# STM32C092 register map
File version: 1.2
CPU: CM0+ r0p0, little endian, MPU, no FPU, 4 interrupt priority bits
Registers are 32-bit, read-write, reset 0x0 unless marked. A register's access mark holds for its fields unless they carry their own. Offsets are from the block's base; [hi:lo] are bit positions; {n}, {i} and the like mark numbered series; 'fields as' and 'values as' point back to an identical list.

## RCC — RCC address block description
Base 0x40021000
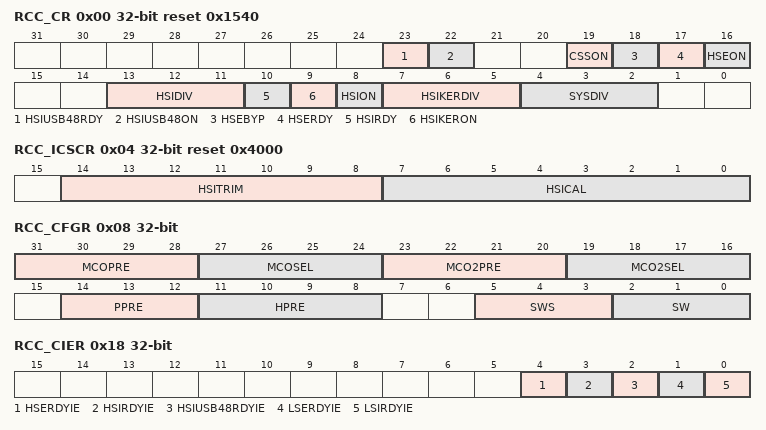
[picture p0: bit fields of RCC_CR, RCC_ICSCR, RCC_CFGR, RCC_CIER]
0x00 RCC_CR reset 0x1540 — RCC clock control register
  [23] HSIUSB48RDY — HSIUSB48 clock ready flag Set by hardware when the HSIUSB48 oscillator is enabled through HSIUSB48ON and ready to use (stable). Note: Only applicable on STM32C071xx, reserved on other devices.
    0=Not ready; 1=Ready
  [22] HSIUSB48ON — HSIUSB48 clock enable Set and cleared by software and hardware, with hardware taking priority. Kept low by hardware as long as the device is in a low-power mode. Kept high by hardware as long as the system is clocked from HSIUSB48. Note: Only applicable on STM32C071xx, reserved on other devices.
    0=Disable; 1=Enable
  [19] CSSON — Clock security system enable Set by software to enable the clock security system. When the bit is set, the clock detector is enabled by hardware when the HSE oscillator is ready, and disabled by hardware if a HSE clock failure is detected. The bit is cleared by hardware upon reset.
    0=Disable; 1=Enable
  [18] HSEBYP — HSE crystal oscillator bypass Set and cleared by software. When the bit is set, the internal HSE oscillator is bypassed for use of an external clock. The external clock must then be enabled with the HSEON bit set. Write access to the bit is only effective when the HSE oscillator is disabled.
    0=No bypass; 1=Bypass
  [17] HSERDY ro — HSE clock ready flag Set by hardware to indicate that the HSE oscillator is stable and ready for use. Note: Upon clearing HSEON, HSERDY goes low after six HSE clock cycles.
    0=Not ready; 1=Ready
  [16] HSEON — HSE clock enable Set and cleared by software. Cleared by hardware to stop the HSE oscillator when entering Stop, or Standby, or Shutdown mode. This bit cannot be cleared if the HSE oscillator is used directly or indirectly as the system clock.
    0=Disable; 1=Enable
  [13:11] HSIDIV — HSI48 clock division factor This bitfield controlled by software sets the division factor of the HSI48 clock divider to produce HSISYS clock:
    0=1; 1=2; 2=4 (reset value); 3=8; 4=16; 5=32; 6=64; 7=128
  [10] HSIRDY ro — HSI48 clock ready flag Set by hardware when the HSI48 oscillator is enabled through HSION and ready to use (stable). Note: Upon clearing HSION, HSIRDY goes low after six HSI48 clock cycles.
    0=Not ready; 1=Ready
  [9] HSIKERON — HSI48 always-enable for peripheral kernels. Set and cleared by software. Setting the bit activates the HSI48 oscillator in Run and Stop modes, regardless of the HSION bit state. The HSI48 clock can only feed USART1, USART2, and I2C1 peripherals configured with HSI48 as kernel clock. Note: Keeping the HSI48 active in Stop mode allows speeding up the serial interface communication as the HSI48 clock is ready immediately upon exiting Stop mode.
    0=HSI48 oscillator enable depends on the HSION bit; 1=HSI48 oscillator is active in Run and Stop modes
  [8] HSION — HSI48 clock enable Set and cleared by software and hardware, with hardware taking priority. Kept low by hardware as long as the device is in a low-power mode. Kept high by hardware as long as the system is clocked with a clock derived from HSI48. This includes the exit from low-power modes and the system clock fall-back to HSI48 upon failing HSE oscillator clock selected as system clock source.
    0=Disable; 1=Enable
  [7:5] HSIKERDIV — HSI48 kernel clock division factor This bitfield controlled by software sets the division factor of the kernel clock divider to produce HSIKER clock:
    0=1; 1=2; 2=3 (reset value); {v}={v+1} (v=3..7)
  [4:2] SYSDIV — Clock division factor for system clock Set and cleared by software. SYSCLK is result of the division by: Note: This bitfield is only available on STM32C071xx.
    0=1 (no division, reset value); {v}={v+1} (v=1..7)
0x04 RCC_ICSCR reset 0x4000 (reset mask 0xFFFFFF00) — RCC internal clock source calibration register
  [14:8] HSITRIM — HSI48 clock trimming The value of this bitfield contributes to the HSICAL[7:0] bitfield value. It allows HSI48 clock frequency user trimming. The HSI48 frequency accuracy as stated in the device datasheet applies when this bitfield is left at its reset value.
  [7:0] HSICAL ro — HSI48 clock calibration This bitfield directly acts on the HSI48 clock frequency. Its value is a sum of an internal factory-programmed number and the value of the HSITRIM[6:0] bitfield. In the factory, the internal number is set to calibrate the HSI48 clock frequency to 48 MHz (with HSITRIM[6:0] left at its reset value). Refer to the device datasheet for HSI48 calibration accuracy and for the frequency trimming granularity. Note: The trimming effect presents discontinuities at HSICAL[7:0] multiples of 64.
0x08 RCC_CFGR — RCC clock configuration register
  [31:28] MCOPRE — Microcontroller clock output prescaler This bitfield is controlled by software. It sets the division factor of the clock sent to the MCO output as follows: ... Other: Reserved It is highly recommended to set this field before the MCO output is enabled. Note: Values above 0111 are only significant for STM32C071xx. On STM32C011xx and STM32C031xx devices, MCOPRE[3] is reserved.
    0=1; 1=2; 2=4; 7=128; 8=256; 9=512; 10=1024
  [27:24] MCOSEL — Microcontroller clock output clock selector This bitfield is controlled by software. It sets the clock selector for MCO output as follows: Other: reserved, must not be used Note: This clock output may have some truncated cycles at startup or during MCO clock source switching. On STM32C011xx and STM32C031xx, MCOSEL[3] is reserved.
    0=no clock; 1=SYSCLK; 3=HSI48; 4=HSE; 6=LSI; 7=LSE; 8=HSIUSB48
  [23:20] MCO2PRE — Microcontroller clock output 2 prescaler This bitfield is controlled by software. It sets the division factor of the clock sent to the MCO2 output as follows: ... Other: Reserved It is highly recommended to set this field before the MCO2 output is enabled. Note: Values above 0111 are only significant for STM32C071xx. On STM32C011xx and STM32C031xx devices, MCOPRE[3] is reserved.
    0=1; 1=2; 2=4; 7=128; 8=256; 9=512; 10=1024
  [19:16] MCO2SEL — Microcontroller clock output 2 clock selector This bitfield is controlled by software. It sets the clock selector for MCO2 output as follows: Other: reserved, must not be used Note: This clock output may have some truncated cycles at startup or during MCO2 clock source switching. On STM32C011xx and STM32C031xx, MCOSEL[3] is reserved.
    values as MCOSEL
  [14:12] PPRE — APB prescaler This bitfield is controlled by software. To produce PCLK clock, it sets the division factor of HCLK clock as follows: 0xx: 1
    4=2; 5=4; 6=8; 7=16
  [11:8] HPRE — AHB prescaler This bitfield is controlled by software. To produce HCLK clock, it sets the division factor of SYSCLK clock as follows: 0xxx: 1
    8=2; 9=4; 10=8; 11=16; 12=64; 13=128; 14=256; 15=512
  [5:3] SWS ro — System clock switch status This bitfield is controlled by hardware to indicate the clock source used as system clock: Others: Reserved
    0=HSISYS; 1=HSE; 3=LSI; 4=LSE
  [2:0] SW — System clock switch This bitfield is controlled by software and hardware. The bitfield selects the clock for SYSCLK as follows: Others: Reserved The setting is forced by hardware to 000 (HSISYS selected) when the MCU exits Stop, or Standby, or Shutdown mode, or when the setting is 001 (HSE selected) and HSE oscillator failure is detected.
    0=HSISYS; 1=HSE; 3=LSI; 4=LSE
0x14 RCC_CRRCR ro (reset mask 0xFFFFFE00) — RCC clock recovery RC register
  [8:0] HSIUSB48CAL — HSIUSB48 clock calibration These bits are initialized at startup with the factory-programmed HSIUSB48 calibration trim value.
0x18 RCC_CIER — RCC clock interrupt enable register
  [all] fields
    0=Disable; 1=Enable
  [4] HSERDYIE — HSE ready interrupt enable Set and cleared by software to enable/disable interrupt caused by the HSE oscillator stabilization:
  [3] HSIRDYIE — HSI48 ready interrupt enable Set and cleared by software to enable/disable interrupt caused by the HSI48 oscillator stabilization:
  [2] HSIUSB48RDYIE — HSIUSB48 ready interrupt enable Set and cleared by software to enable/disable interrupt caused by the HSIUSB48 oscillator stabilization: Note: Only applicable on STM32C071xx, reserved on other devices.
  [1] LSERDYIE — LSE ready interrupt enable Set and cleared by software to enable/disable interrupt caused by the LSE oscillator stabilization:
  [0] LSIRDYIE — LSI ready interrupt enable Set and cleared by software to enable/disable interrupt caused by the LSI oscillator stabilization:
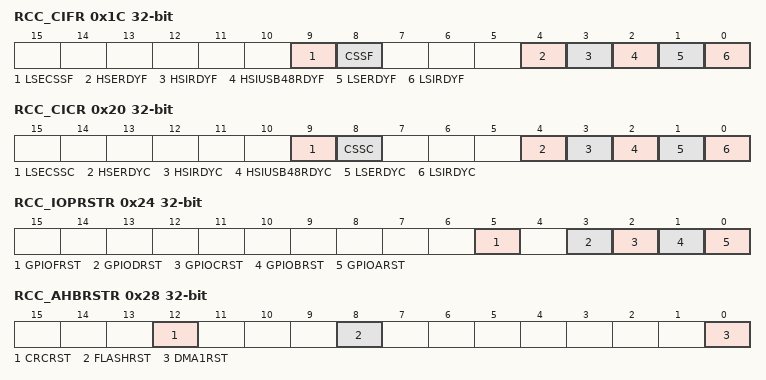
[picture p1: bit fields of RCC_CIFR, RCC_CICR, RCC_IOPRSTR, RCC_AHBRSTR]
0x1C RCC_CIFR ro — RCC clock interrupt flag register
  [all] fields
    0=Interrupt not pending; 1=Interrupt pending
  [9] LSECSSF — LSE clock security system interrupt flag This flag indicates a pending interrupt upon LSE clock failure. Set by hardware when a failure is detected in the LSE oscillator. Cleared by software by setting the LSECSSC bit.
  [8] CSSF — HSE clock security system interrupt flag This flag indicates a pending interrupt upon HSE clock failure. Set by hardware when a failure is detected in the HSE oscillator. Cleared by software setting the CSSC bit.
  [4] HSERDYF — HSE ready interrupt flag This flag indicates a pending interrupt upon HSE clock getting ready. Set by hardware when the HSE clock becomes stable and HSERDYIE is set. Cleared by software setting the HSERDYC bit.
  [3] HSIRDYF — HSI48 ready interrupt flag This flag indicates a pending interrupt upon HSI48 clock getting ready. Set by hardware when the HSI48 clock becomes stable and HSIRDYIE is set in response to setting the HSION (refer to RCC clock control register (RCC_CR)). When HSION is not set but the HSI48 oscillator is enabled by the peripheral through a clock request, this bit is not set and no interrupt is generated. Cleared by software setting the HSIRDYC bit.
  [2] HSIUSB48RDYF — HSIUSB48 ready interrupt flag Set by hardware when the HSIUSB48 clock becomes stable and HSIUSB48RDYIE is set as a response to setting HSIUSB48ON (refer to RCC clock control register (RCC_CR)). When HSIUSB48ON is not set but the HSIUSB48 oscillator is enabled by the peripheral through a clock request, this bit is not set and no interrupt is generated. Cleared by software setting the HSIUSB48RDYC bit. Note: Only applicable on STM32C071xx, reserved on other devices.
  [1] LSERDYF — LSE ready interrupt flag This flag indicates a pending interrupt upon LSE clock getting ready. Set by hardware when the LSE clock becomes stable and LSERDYDIE is set. Cleared by software setting the LSERDYC bit.
  [0] LSIRDYF — LSI ready interrupt flag This flag indicates a pending interrupt upon LSE clock getting ready. Set by hardware when the LSI clock becomes stable and LSIRDYDIE is set. Cleared by software setting the LSIRDYC bit.
0x20 RCC_CICR wo — RCC clock interrupt clear register
  [9] LSECSSC — LSE Clock security system interrupt clear This bit is set by software to clear the LSECSSF flag.
    0=No effect; 1=Clear LSECSSF flag
  [8] CSSC — Clock security system interrupt clear This bit is set by software to clear the HSECSSF flag.
    0=No effect; 1=Clear CSSF flag
  [4] HSERDYC — HSE ready interrupt clear This bit is set by software to clear the HSERDYF flag.
    0=No effect; 1=Clear HSERDYF flag
  [3] HSIRDYC — HSI48 ready interrupt clear This bit is set software to clear the HSIRDYF flag.
    0=No effect; 1=Clear HSIRDYF flag
  [2] HSIUSB48RDYC — HSIUSB48 ready interrupt clear This bit is set software to clear the HSIUSB48RDYF flag. Note: Only applicable on STM32C071xx, reserved on other devices.
    0=No effect; 1=Clear HSIUSB48RDYF flag
  [1] LSERDYC — LSE ready interrupt clear This bit is set by software to clear the LSERDYF flag.
    0=No effect; 1=Clear LSERDYF flag
  [0] LSIRDYC — LSI ready interrupt clear This bit is set by software to clear the LSIRDYF flag.
    0=No effect; 1=Clear LSIRDYF flag
0x24 RCC_IOPRSTR — RCC I/O port reset register
  [5] GPIOFRST — I/O port F reset This bit is set and cleared by software.
    0=no effect; 1=Reset I/O port F
  [3] GPIODRST — I/O port D reset This bit is set and cleared by software.
    0=no effect; 1=Reset I/O port D
  [2] GPIOCRST — I/O port C reset This bit is set and cleared by software.
    0=no effect; 1=Reset I/O port C
  [1] GPIOBRST — I/O port B reset This bit is set and cleared by software.
    0=no effect; 1=Reset I/O port B
  [0] GPIOARST — I/O port A reset This bit is set and cleared by software.
    0=no effect; 1=Reset I/O port A
0x28 RCC_AHBRSTR — RCC AHB peripheral reset register
  [12] CRCRST — CRC reset Set and cleared by software.
    0=No effect; 1=Reset CRC
  [8] FLASHRST — Flash memory interface reset Set and cleared by software. This bit can only be set when the Flash memory is in power down mode.
    0=No effect; 1=Reset Flash memory interface
  [0] DMA1RST — DMA1 and DMAMUX reset Set and cleared by software.
    0=No effect; 1=Reset DMA1 and DMAMUX
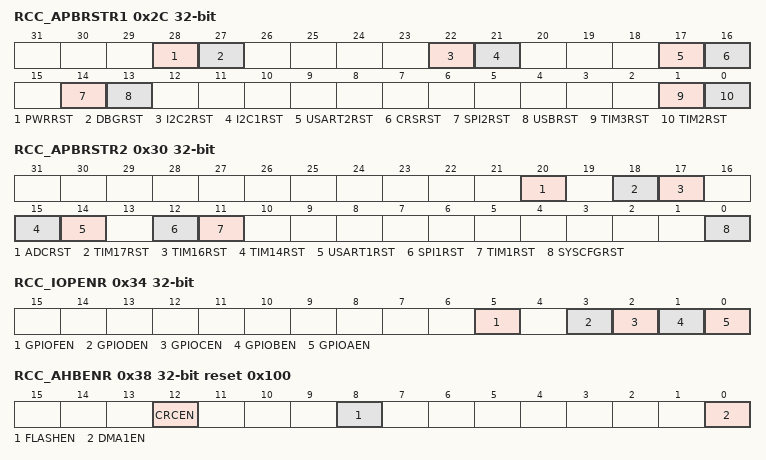
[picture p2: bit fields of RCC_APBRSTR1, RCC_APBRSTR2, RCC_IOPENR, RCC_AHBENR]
0x2C RCC_APBRSTR1 — RCC APB peripheral reset register 1
  [28] PWRRST — Power interface reset Set and cleared by software.
    0=No effect; 1=Reset PWR
  [27] DBGRST — Debug support reset Set and cleared by software.
    0=No effect; 1=Reset DBG
  [22] I2C2RST — I2C2 reset Set and cleared by software. Note: Only applicable on STM32C071xx, reserved on other devices.
    0=No effect; 1=Reset I2C2
  [21] I2C1RST — I2C1 reset Set and cleared by software.
    0=No effect; 1=Reset I2C1
  [17] USART2RST — USART2 reset Set and cleared by software.
    0=No effect; 1=Reset USART2
  [16] CRSRST — CRS reset Set and cleared by software. Note: Only applicable on STM32C071xx, reserved on other devices.
    0=No effect; 1=Reset CRS
  [14] SPI2RST — SPI2 reset Set and cleared by software. Note: Only applicable on STM32C071xx, reserved on other devices.
    0=No effect; 1=Reset SPI2
  [13] USBRST — USB reset Set and cleared by software. Note: Only applicable on STM32C071xx, reserved on other devices.
    0=No effect; 1=Reset USB
  [1] TIM3RST — TIM3 timer reset Set and cleared by software.
    0=No effect; 1=Reset TIM3
  [0] TIM2RST — TIM2 timer reset Set and cleared by software. Note: Only applicable on STM32C071xx, reserved on other devices.
    0=No effect; 1=Reset TIM2
0x30 RCC_APBRSTR2 — RCC APB peripheral reset register 2
  [20] ADCRST — ADC reset Set and cleared by software.
    0=No effect; 1=Reset ADC
  [18] TIM17RST — TIM16 timer reset Set and cleared by software.
    0=No effect; 1=Reset TIM17 timer
  [17] TIM16RST — TIM16 timer reset Set and cleared by software.
    0=No effect; 1=Reset TIM16 timer
  [15] TIM14RST — TIM14 timer reset Set and cleared by software.
    0=No effect; 1=Reset TIM14 timer
  [14] USART1RST — USART1 reset Set and cleared by software.
    0=No effect; 1=Reset USART1
  [12] SPI1RST — SPI1 reset Set and cleared by software.
    0=No effect; 1=Reset SPI1
  [11] TIM1RST — TIM1 timer reset Set and cleared by software.
    0=No effect; 1=Reset TIM1 timer
  [0] SYSCFGRST — SYSCFG reset Set and cleared by software.
    0=No effect; 1=Reset SYSCFG
0x34 RCC_IOPENR — RCC I/O port clock enable register
  [all] fields
    0=Disable; 1=Enable
  [5] GPIOFEN — I/O port F clock enable This bit is set and cleared by software.
  [3] GPIODEN — I/O port D clock enable This bit is set and cleared by software.
  [2] GPIOCEN — I/O port C clock enable This bit is set and cleared by software.
  [1] GPIOBEN — I/O port B clock enable This bit is set and cleared by software.
  [0] GPIOAEN — I/O port A clock enable This bit is set and cleared by software.
0x38 RCC_AHBENR reset 0x100 — RCC AHB peripheral clock enable register
  [all] fields
    0=Disable; 1=Enable
  [12] CRCEN — CRC clock enable Set and cleared by software.
  [8] FLASHEN — Flash memory interface clock enable Set and cleared by software. This bit can only be cleared when the Flash memory is in power down mode.
  [0] DMA1EN — DMA1 and DMAMUX clock enable Set and cleared by software. DMAMUX is enabled as long as at least one DMA peripheral is enabled.
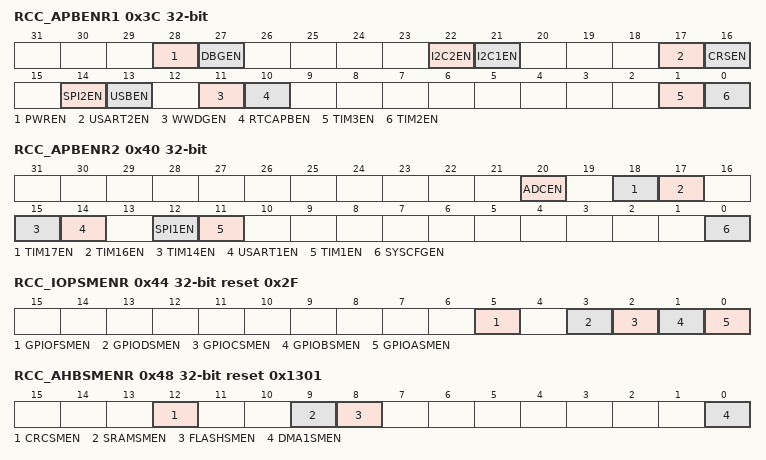
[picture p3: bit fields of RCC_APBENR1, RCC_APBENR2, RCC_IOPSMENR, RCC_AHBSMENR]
0x3C RCC_APBENR1 — RCC APB peripheral clock enable register 1
  [all] fields
    0=Disable; 1=Enable
  [28] PWREN — Power interface clock enable Set and cleared by software.
  [27] DBGEN — Debug support clock enable Set and cleared by software.
  [22] I2C2EN — I2C2 clock enable Set and cleared by software.
  [21] I2C1EN — I2C1 clock enable Set and cleared by software.
  [17] USART2EN — USART2 clock enable Set and cleared by software.
  [16] CRSEN — CRS clock enable Set and cleared by software.
  [14] SPI2EN — SPI2 clock enable Set and cleared by software.
  [13] USBEN — USB clock enable Set and cleared by software.
  [11] WWDGEN — WWDG clock enable Set by software to enable the window watchdog clock. Cleared by hardware system reset This bit can also be set by hardware if the WWDG_SW option bit is 0.
  [10] RTCAPBEN — RTC APB clock enable Set and cleared by software.
  [1] TIM3EN — TIM3 timer clock enable Set and cleared by software.
  [0] TIM2EN — TIM2 timer clock enable Set and cleared by software.
0x40 RCC_APBENR2 — RCC APB peripheral clock enable register 2
  [all] fields
    0=Disable; 1=Enable
  [20] ADCEN — ADC clock enable Set and cleared by software.
  [18] TIM17EN — TIM16 timer clock enable Set and cleared by software.
  [17] TIM16EN — TIM16 timer clock enable Set and cleared by software.
  [15] TIM14EN — TIM14 timer clock enable Set and cleared by software.
  [14] USART1EN — USART1 clock enable Set and cleared by software.
  [12] SPI1EN — SPI1 clock enable Set and cleared by software.
  [11] TIM1EN — TIM1 timer clock enable Set and cleared by software.
  [0] SYSCFGEN — SYSCFG clock enable Set and cleared by software.
0x44 RCC_IOPSMENR reset 0x2F — RCC I/O port in Sleep mode clock enable register
  [all] fields
    0=Disable; 1=Enable
  [5] GPIOFSMEN — I/O port F clock enable during Sleep mode Set and cleared by software.
  [3] GPIODSMEN — I/O port D clock enable during Sleep mode Set and cleared by software.
  [2] GPIOCSMEN — I/O port C clock enable during Sleep mode Set and cleared by software.
  [1] GPIOBSMEN — I/O port B clock enable during Sleep mode Set and cleared by software.
  [0] GPIOASMEN — I/O port A clock enable during Sleep mode Set and cleared by software.
0x48 RCC_AHBSMENR reset 0x1301 — RCC AHB peripheral clock enable in Sleep/Stop mode register
  [all] fields
    0=Disable; 1=Enable
  [12] CRCSMEN — CRC clock enable during Sleep mode Set and cleared by software.
  [9] SRAMSMEN — SRAM clock enable during Sleep mode Set and cleared by software.
  [8] FLASHSMEN — Flash memory interface clock enable during Sleep mode Set and cleared by software. This bit can be activated only when the Flash memory is in power down mode.
  [0] DMA1SMEN — DMA1 and DMAMUX clock enable during Sleep mode Set and cleared by software. Clock to DMAMUX during Sleep mode is enabled as long as the clock in Sleep mode is enabled to at least one DMA peripheral.
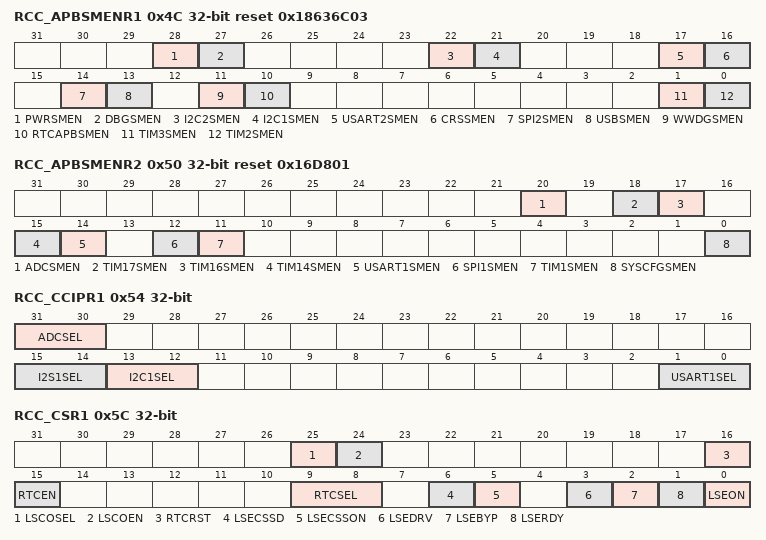
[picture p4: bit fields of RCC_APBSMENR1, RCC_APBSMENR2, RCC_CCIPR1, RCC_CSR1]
0x4C RCC_APBSMENR1 reset 0x18636C03 — RCC APB peripheral clock enable in Sleep/Stop mode register 1
  [all] fields
    0=Disable; 1=Enable
  [28] PWRSMEN — Power interface clock enable during Sleep mode Set and cleared by software.
  [27] DBGSMEN — Debug support clock enable during Sleep mode Set and cleared by software.
  [22] I2C2SMEN — I2C2 clock enable during Sleep and Stop modes Set and cleared by software. Note: Only applicable on STM32C071xx, reserved on other devices.
  [21] I2C1SMEN — I2C1 clock enable during Sleep and Stop modes Set and cleared by software.
  [17] USART2SMEN — USART2 clock enable during Sleep and Stop modes Set and cleared by software.
  [16] CRSSMEN — CRS clock enable during Sleep and Stop modes Set and cleared by software. Note: Only applicable on STM32C071xx, reserved on other devices.
  [14] SPI2SMEN — SPI2 clock enable during Sleep and Stop modes Set and cleared by software. Note: Only applicable on STM32C071xx, reserved on other devices.
  [13] USBSMEN — USB clock enable during Sleep and Stop modes Set and cleared by software. Note: Only applicable on STM32C071xx, reserved on other devices.
  [11] WWDGSMEN — WWDG clock enable during Sleep and Stop modes Set and cleared by software.
  [10] RTCAPBSMEN — RTC APB clock enable during Sleep mode Set and cleared by software.
  [1] TIM3SMEN — TIM3 timer clock enable during Sleep mode Set and cleared by software.
  [0] TIM2SMEN — TIM2 timer clock enable during Sleep mode Set and cleared by software. Note: Only applicable on STM32C071xx, reserved on other devices.
0x50 RCC_APBSMENR2 reset 0x16D801 — RCC APB peripheral clock enable in Sleep/Stop mode register 2
  [all] fields
    0=Disable; 1=Enable
  [20] ADCSMEN — ADC clock enable during Sleep mode Set and cleared by software.
  [18] TIM17SMEN — TIM16 timer clock enable during Sleep mode Set and cleared by software.
  [17] TIM16SMEN — TIM16 timer clock enable during Sleep mode Set and cleared by software.
  [15] TIM14SMEN — TIM14 timer clock enable during Sleep mode Set and cleared by software.
  [14] USART1SMEN — USART1 clock enable during Sleep and Stop modes Set and cleared by software.
  [12] SPI1SMEN — SPI1 clock enable during Sleep mode Set and cleared by software.
  [11] TIM1SMEN — TIM1 timer clock enable during Sleep mode Set and cleared by software.
  [0] SYSCFGSMEN — SYSCFG clock enable during Sleep and Stop modes Set and cleared by software.
0x54 RCC_CCIPR1 — RCC peripherals independent clock configuration register 1
  [31:30] ADCSEL — ADCs clock source selection This bitfield is controlled by software to select the asynchronous clock source for ADC:
    0=System clock; 2=HSIKER
  [15:14] I2S1SEL — I2S1 clock source selection This bitfield is controlled by software to select I2S1 clock source as follows:
    0=SYSCLK; 2=HSIKER; 3=I2S_CKIN
  [13:12] I2C1SEL — I2C1 clock source selection This bitfield is controlled by software to select I2C1 clock source as follows:
    0=PCLK; 1=SYSCLK; 2=HSIKER
  [1:0] USART1SEL — USART1 clock source selection This bitfield is controlled by software to select USART1 clock source as follows:
    0=PCLK; 1=SYSCLK; 2=HSIKER; 3=LSE
0x58 RCC_CCIPR2 — RCC peripherals independent clock configuration register 2
  [12] USBSEL — USB clock source selection Set and cleared by software.
    0=HSIUSB48; 1=HSE
0x5C RCC_CSR1 — RCC control/status register 1
  [25] LSCOSEL — Low-speed clock output selection Set and cleared by software to select the low-speed output clock:
    0=LSI; 1=LSE
  [24] LSCOEN — Low-speed clock output (LSCO) enable Set and cleared by software.
    0=Disable; 1=Enable
  [16] RTCRST — RTC domain software reset Set and cleared by software to reset the RTC domain:
    0=No effect; 1=Reset
  [15] RTCEN — RTC clock enable Set and cleared by software. The bit enables clock to RTC and TAMP.
    0=Disable; 1=Enable
  [9:8] RTCSEL — RTC clock source selection Set by software to select the clock source for the RTC as follows: Once the RTC clock source is selected, it cannot be changed anymore unless the RTC domain is reset, or unless a failure is detected on LSE (LSECSSD is set). The RTCRST bit can be used to reset this bitfield to 00.
    0=No clock; 1=LSE; 2=LSI; 3=HSE divided by 32
  [6] LSECSSD ro — CSS on LSE failure Detection Set by hardware to indicate when a failure is detected by the clock security system on the external 32 kHz oscillator (LSE):
    0=No failure detected; 1=Failure detected
  [5] LSECSSON — CSS on LSE enable Set by software to enable the clock security system on LSE (32 kHz) oscillator as follows: LSECSSON must be enabled after the LSE oscillator is enabled (LSEON bit enabled) and ready (LSERDY flag set by hardware), and after the RTCSEL bit is selected. Once enabled, this bit cannot be disabled, except after a LSE failure detection (LSECSSD =1). In that case the software must disable the LSECSSON bit.
    0=Disable; 1=Enable
  [3] LSEDRV — LSE oscillator drive capability Set by software to select the LSE oscillator drive capability as follows: Applicable when the LSE oscillator is in Xtal mode, as opposed to bypass mode.
    0=medium-high driving capability; 1=high driving capability
  [2] LSEBYP — LSE oscillator bypass Set and cleared by software to bypass the LSE oscillator (in debug mode). This bit can be written only when the external 32 kHz oscillator is disabled (LSEON=0 and LSERDY=0).
    0=Not bypassed; 1=Bypassed
  [1] LSERDY ro — LSE oscillator ready Set and cleared by hardware to indicate when the external 32 kHz oscillator is ready (stable): After the LSEON bit is cleared, LSERDY goes low after 6 external low-speed oscillator clock cycles.
    0=Not ready; 1=Ready
  [0] LSEON — LSE oscillator enable Set and cleared by software to enable LSE oscillator:
    0=Disable; 1=Enable
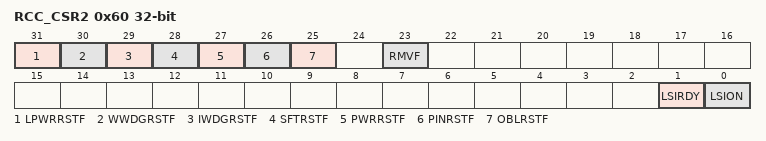
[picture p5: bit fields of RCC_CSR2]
0x60 RCC_CSR2 — RCC control/status register 2
  [31] LPWRRSTF ro — Low-power reset flag Set by hardware when a reset occurs due to illegal Stop, or Standby, or Shutdown mode entry. Cleared by setting the RMVF bit. This operates only if nRST_STOP, or nRST_STDBY or nRST_SHDW option bits are cleared.
    0=No illegal mode reset occurred; 1=Illegal mode reset occurred
  [30] WWDGRSTF ro — Window watchdog reset flag Set by hardware when a window watchdog reset occurs. Cleared by setting the RMVF bit.
    0=No window watchdog reset occurred; 1=Window watchdog reset occurred
  [29] IWDGRSTF ro — Independent window watchdog reset flag Set by hardware when an independent watchdog reset domain occurs. Cleared by setting the RMVF bit.
    0=No independent watchdog reset occurred; 1=Independent watchdog reset occurred
  [28] SFTRSTF ro — Software reset flag Set by hardware when a software reset occurs. Cleared by setting the RMVF bit.
    0=No software reset occurred; 1=Software reset occurred
  [27] PWRRSTF ro — BOR or POR/PDR flag Set by hardware when a BOR or POR/PDR occurs. Cleared by setting the RMVF bit.
    0=No BOR or POR occurred; 1=BOR or POR occurred
  [26] PINRSTF ro — Pin reset flag Set by hardware when a reset from the NRST pin occurs. Cleared by setting the RMVF bit.
    0=No reset from NRST pin occurred; 1=Reset from NRST pin occurred
  [25] OBLRSTF ro — Option byte loader reset flag Set by hardware when a reset from the Option byte loading occurs. Cleared by setting the RMVF bit.
    0=No reset from Option byte loading occurred; 1=Reset from Option byte loading occurred
  [23] RMVF — Remove reset flags Set by software to clear the reset flags.
    0=No effect; 1=Clear reset flags
  [1] LSIRDY ro — LSI oscillator ready Set and cleared by hardware to indicate when the LSI oscillator is ready (stable): After the LSION bit is cleared, LSIRDY goes low after 3 LSI oscillator clock cycles. This bit can be set even if LSION = 0 if the LSI is requested by the Clock Security System on LSE, by the Independent Watchdog or by the RTC.
    0=Not ready; 1=Ready
  [0] LSION — LSI oscillator enable Set and cleared by software to enable/disable the LSI oscillator:
    0=Disable; 1=Enable
